# ATUC64L4U device description
Architecture: AVR32_UC3; Family: AVR UC3
Registers are 32-bit, read-write, reset 0x0 unless marked. A register's access mark holds for its fields unless they carry their own. Offsets are from the block's base; [hi:lo] are bit positions; lines under a group give offsets from that group; {n}, {i} and the like mark numbered series.

## PWMA — Pulse Width Modulation Controller
Instances: PWMA 0xffff5400
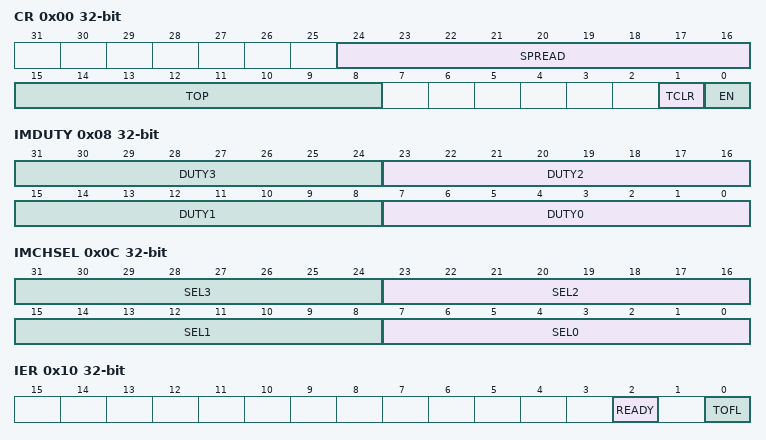
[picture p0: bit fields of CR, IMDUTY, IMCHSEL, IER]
0x00 CR — Control Register
  [24:16] SPREAD — Spread Spectrum Counter Value
  [15:8] TOP — Timebase Counter Top Value
  [1] TCLR — Timebase Clear
  [0] EN — Module enable
0x04 ISDUTY wo — Interlinked Single Value Duty Register
  [11:0] DUTY — Duty Cycle Value
0x08 IMDUTY wo — Interlinked Multiple Value Duty Register
  [8n+7:8n] DUTY{n} (n=0..3) — Duty cycle
0x0C IMCHSEL wo — Interlinked Multiple Value Channel Select
  [8n+7:8n] SEL{n} (n=0..3) — Channel Select {n}
0x10 IER wo — Interrupt Enable Register
  [2] READY — Interface Ready
  [0] TOFL — Timebase Overflow
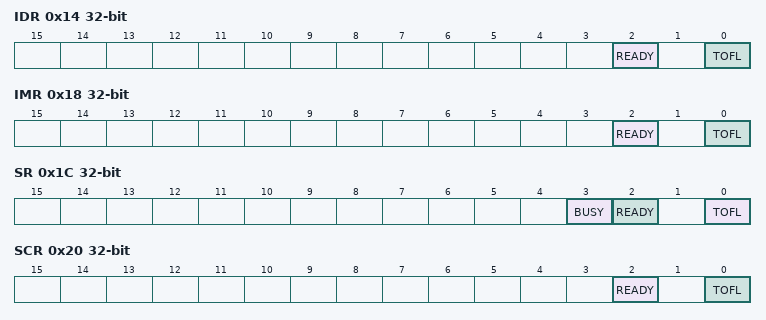
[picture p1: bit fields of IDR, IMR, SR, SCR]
0x14 IDR wo — Interrupt Disable Register
  [2] READY — Interface Ready
  [0] TOFL — Timebase Overflow
0x18 IMR ro — Interrupt Mask Register
  [2] READY — Interface Ready
  [0] TOFL — Timebase Overflow
0x1C SR ro — Status Register
  [3] BUSY — Interface Busy
  [2] READY — Interface Ready
  [0] TOFL — Timebase Overflow
0x20 SCR wo — Status Clear Register
  [2] READY — Interface Ready
  [0] TOFL — Timebase Overflow
0x24 PARAMETER ro reset 0x24
  [7:0] CHANNELS — Channels implemented
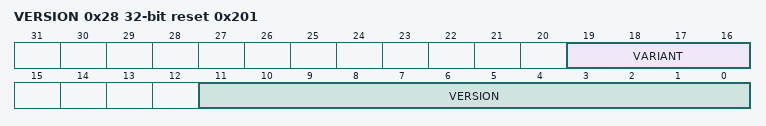
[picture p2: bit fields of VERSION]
0x28 VERSION ro reset 0x201
  [19:16] VARIANT — Variant number
  [11:0] VERSION — Version number
0x2C TVR — Top Value Register
  [11:0] TOP — Timebase Counter Top Value
{0x30+0x10*i} CHGROUP[{i}] (i=0..4) group
  0x00 ISCHSET wo — Interlinked Single Value Channel Set
    [31:0] SET — Single Value Channel Set
  0x04 CHERR — Channel Event Response Register
    [31:0] CHER — Channel Event Response
  0x08 CHEER — Channel Event Enable Register
    [31:0] CHEE — Channel Event Enable
  0x0C CWG — Composite Waveform Generator
    [31:0] XOR — Pair Waveform XORed
{0x80+4i} DUTY{i} wo (i=0..3) — Duty Value Register {i}
  [11:0] DUTY — Duty Cycle Value

## SAU — Secure Access Unit
Instances: SAU 0xfffe0800, SAU_HSB 0x90000000 in hsb
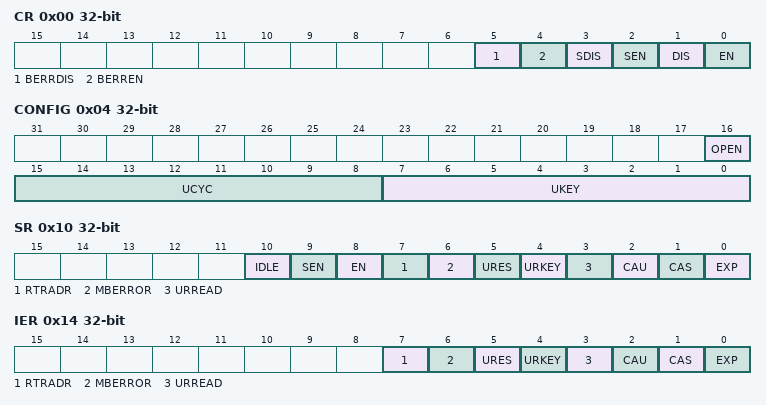
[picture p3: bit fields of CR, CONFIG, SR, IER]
0x00 CR wo reset not defined — Control Register
  [5] BERRDIS — Bus Error Response Disable
  [4] BERREN — Bus Error Response Enable
  [3] SDIS — Setup Mode Disable
  [2] SEN — Setup Mode Enable
  [1] DIS — SAU Disable
  [0] EN — SAU Enable
0x04 CONFIG wo — Configuration Register
  [16] OPEN — Open Mode Enable
  [15:8] UCYC — Unlock number of clock cycles
  [7:0] UKEY — Unlock Key
0x08 CERH — Channel Enable Register High
  [30:0] CERH
0x0C CERL — Channel Enable Register Low
0x10 SR ro — Status Register
  [10] IDLE — SAU Master Interface Idle
  [9] SEN — SAU Setup Mode Enabled
  [8] EN — SAU Enabled
  [7] RTRADR — RTR Address Error
  [6] MBERROR — Master Interface Bus Error
  [5] URES — Unlock Register Error
  [4] URKEY — Unlock Register Key Error
  [3] URREAD — Unlock Register Read
  [2] CAU — Channel Access Unsuccessful
  [1] CAS — Channel Access Successful
  [0] EXP — Channel Unlock Expired
0x14 IER wo reset not defined — Interrupt Enable Register
  [7] RTRADR — Enable Illegal RTR Address Setup Interrupt
  [6] MBERROR — Enable Master Interface Bus Error Interrupt
  [5] URES — Enable Unlock Register Error Interrupt
  [4] URKEY — Enable Unlock Register Key Error Interrupt
  [3] URREAD — Enable Unlock Register Read Interrupt
  [2] CAU — Enable Channel Access Unsuccessful Interrupt
  [1] CAS — Enable Channel Access Successful Interrupt
  [0] EXP — Enable Channel Unlock Expired Interrupt
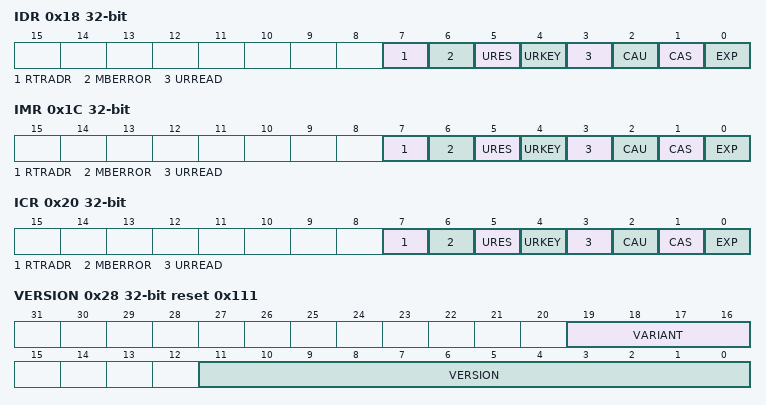
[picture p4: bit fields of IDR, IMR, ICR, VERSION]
0x18 IDR wo reset not defined — Interrupt Disable Register
  [7] RTRADR — Disable Illegal RTR Address Setup Interrupt
  [6] MBERROR — Disable Master Interface Bus Error Interrupt
  [5] URES — Disable Inlock Register Error Interrupt
  [4] URKEY — Disable Unlock Register Key Error Interrupt
  [3] URREAD — Disable Unlock Register Read Interrupt
  [2] CAU — Disable Channel Access Unsuccessful Interrupt
  [1] CAS — Disable Channel Access Successful Interrupt
  [0] EXP — Disable Channel Unlock Expired Interrupt
0x1C IMR ro — Interrupt Mask Register
  [7] RTRADR — Illegal RTR Address Setup Interrupt Mask Bit
  [6] MBERROR — Master Interface Bus Error Interrupt Mask Bit
  [5] URES — Unlock Register Error Interrupt Mask Bit
  [4] URKEY — Unlock Register Key Error Interrupt Mask Bit
  [3] URREAD — Unlock Register Read Interrupt Mask Bit
  [2] CAU — Channel Access Unsuccessful Interrupt Mask Bit
  [1] CAS — Channel Access Successful Interrupt Mask Bit
  [0] EXP — Channel Unlock Expired Interrupt Mask Bit
0x20 ICR wo reset not defined — Interrupt Clear Register
  [7] RTRADR — Clear Illegal RTR Address Setup bit
  [6] MBERROR — Clear Master Interface Bus Error bit
  [5] URES — Clear Unlock Register Error bit
  [4] URKEY — Clear Unlock Register Key Error bit
  [3] URREAD — Clear Unlock Register Read bit
  [2] CAU — Clear Channel Access Unsuccessful bit
  [1] CAS — Clear Channel Access Successful bit
  [0] EXP — Clear Channel Unlock Expired bit
0x24 PARAMETER ro reset 0x10
  [5:0] CHANNELS — SAU Parameters
0x28 VERSION ro reset 0x111
  [19:16] VARIANT — Variant number
  [11:0] VERSION — Version number
